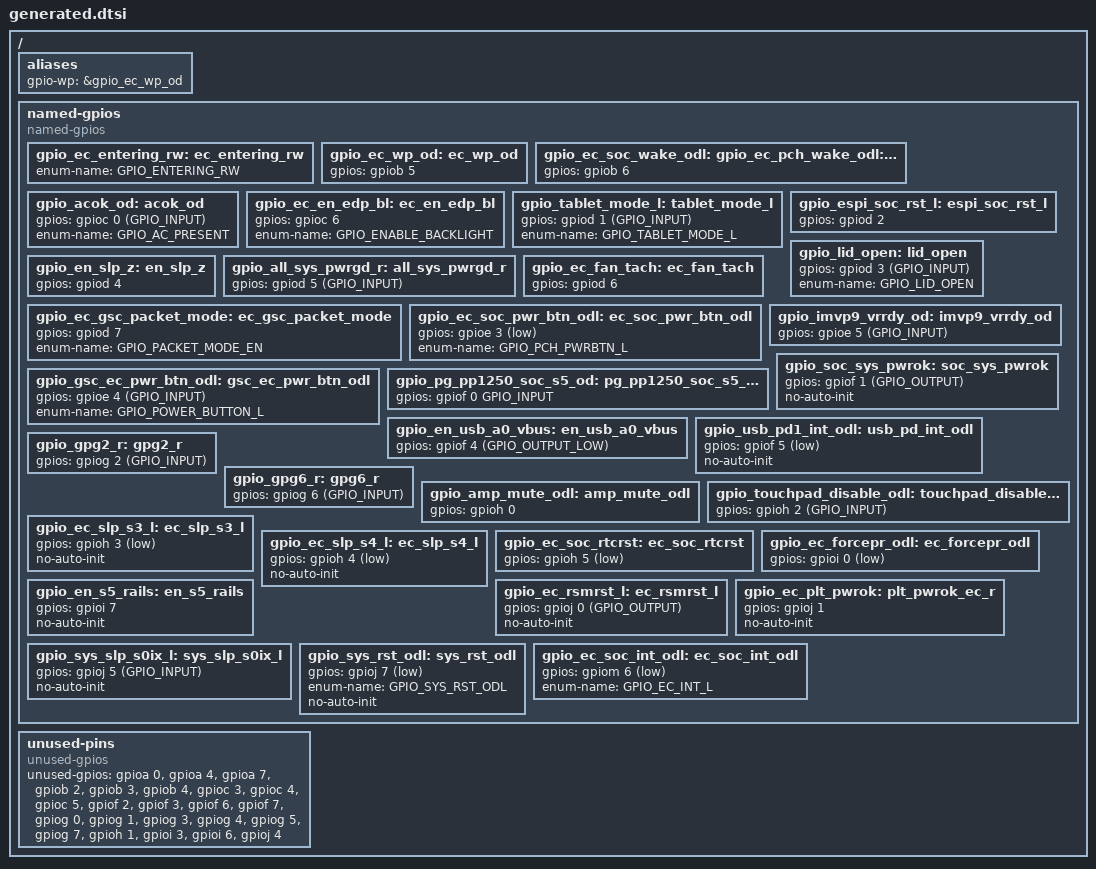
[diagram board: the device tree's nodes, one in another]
/* Copyright 2025 The ChromiumOS Authors
 * Use of this source code is governed by a BSD-style license that can be
 * found in the LICENSE file.
 */

/ {
	aliases {
		gpio-wp = &gpio_ec_wp_od;
	};

	named-gpios {
		compatible = "named-gpios";

		/* The legacy system code requires GPIO_ENTERING_RW symbol */
		gpio_ec_entering_rw: ec_entering_rw {
			enum-name = "GPIO_ENTERING_RW";
		};
            /*********** Port A *****************/
        /* GPA0: EC_KB_CAP_LED_L    */
        /* GPA1: PWM-EC_KB_BL_PWM   */
        /* GPA2: PWM-CHG_LED#_EC    */
        /* GPA3: PWM-AC_LED#_EC     */
        /* GPA4: FN_LED_L           */
		/* GPA5: PWM-PWR_LED_L      */
        /* GPA6: PWM-FAN_PWM_OD     */
        /* GPA7: ME_FLASH_EN_N      */

            /*********** Port B *****************/
        /* GPB0: UART_EC_RX_GSC_DBG_TX */
        /* GPB1: UART_EC_TX_GSC_DBG_RX */
        /* GPB2: NC                    */
		/* GPB3: tchscr_int_l		   */
        /* GPB4: CAMERA_WP_EC          */
		gpio_ec_wp_od: ec_wp_od {
			gpios = <&gpiob 5 (GPIO_INPUT | GPIO_ACTIVE_HIGH)>;
		};
		gpio_ec_soc_wake_odl: ec_soc_wake_odl {
			gpios = <&gpiob 6 (GPIO_OUTPUT | GPIO_OPEN_DRAIN | GPIO_ACTIVE_HIGH | GPIO_OUTPUT_INIT_HIGH)>;
		};

            /*********** Port C *****************/
		gpio_acok_od: acok_od {
			gpios = <&gpioc 0 (GPIO_INPUT)>;
			enum-name = "GPIO_AC_PRESENT";
		};
        /* GPC1: EC_I2C_PD_SCL          */
        /* GPC2: EC_I2C_PD_SDA          */
        /* GPC3: CPU_ID                 */
		/* GPC4: tchscr_report_en		*/
        /* GPC5: EC_PROJECT_ID          */
		gpio_ec_en_edp_bl: ec_en_edp_bl {
			gpios = <&gpioc 6 (GPIO_OUTPUT | GPIO_ACTIVE_HIGH | GPIO_OUTPUT_INIT_HIGH)>;
			enum-name = "GPIO_ENABLE_BACKLIGHT";
		};
        /* GPC7: EC_I2C_PROG_SCL        */

            /*********** Port D *****************/
        /* GPD0: EC_I2C_PROG_SDA        */
		gpio_tablet_mode_l: tablet_mode_l {
			gpios = <&gpiod 1 (GPIO_INPUT)>;
			enum-name = "GPIO_TABLET_MODE_L";
		};
		gpio_espi_soc_rst_l: espi_soc_rst_l {
			gpios = <&gpiod 2 (GPIO_INPUT | GPIO_VOLTAGE_1P8)>;
		};
		gpio_lid_open: lid_open {
			gpios = <&gpiod 3 (GPIO_INPUT)>;
			enum-name = "GPIO_LID_OPEN";
		};
		gpio_en_slp_z: en_slp_z {
			gpios = <&gpiod 4 (GPIO_OUTPUT | GPIO_ACTIVE_HIGH)>;
		};
		gpio_all_sys_pwrgd_r: all_sys_pwrgd_r {
			gpios = <&gpiod 5 (GPIO_INPUT)>;
		};
		gpio_ec_fan_tach: ec_fan_tach {
			gpios = <&gpiod 6 (GPIO_INPUT | GPIO_PULL_UP)>;
		};
		gpio_ec_gsc_packet_mode: ec_gsc_packet_mode {
			gpios = <&gpiod 7 (GPIO_OUTPUT | GPIO_ACTIVE_HIGH | GPIO_OUTPUT_INIT_LOW)>;
			enum-name = "GPIO_PACKET_MODE_EN";
		};

            /*********** Port E *****************/
        /* GPE0: EC_I2C_CHARGER_SCL     */
        /* GPE1: ISH_EC_I2C_SENSOR_SCL  */
        /* GPE2: ISH_EC_I2C_SENSOR_SDA  */
		gpio_ec_soc_pwr_btn_odl: ec_soc_pwr_btn_odl {
			gpios = <&gpioe 3 (GPIO_OUTPUT | GPIO_OPEN_DRAIN | GPIO_ACTIVE_LOW)>;
			enum-name = "GPIO_PCH_PWRBTN_L";
		};
		gpio_gsc_ec_pwr_btn_odl: gsc_ec_pwr_btn_odl {
			gpios = <&gpioe 4 (GPIO_INPUT)>;
			enum-name = "GPIO_POWER_BUTTON_L";
		};
		gpio_imvp9_vrrdy_od: imvp9_vrrdy_od {
			gpios = <&gpioe 5 (GPIO_INPUT)>;
		};
        /* GPE6: USB_C0_HV_DISABLE_EC   */
        /* GPE7: EC_I2C_CHARGER_SDA     */

            /*********** Port F *****************/
		gpio_pg_pp1250_soc_s5_od: pg_pp1250_soc_s5_od {
			gpios = <&gpiof 0 GPIO_INPUT>;
		};
		gpio_soc_sys_pwrok: soc_sys_pwrok {
			gpios = <&gpiof 1 (GPIO_OUTPUT)>;
			no-auto-init;
		};
        /* GPF2: PHASE_ID               */
		gpio_en_usb_a0_vbus: en_usb_a0_vbus {
			gpios = <&gpiof 4 (GPIO_OUTPUT_LOW)>;
		};
		gpio_usb_pd1_int_odl: usb_pd_int_odl {
			gpios = <&gpiof 5 (GPIO_INPUT | GPIO_ACTIVE_LOW)>;
			no-auto-init;
		};
        /* GPF6: EC_ACCEL_DB_INT_L      */
        /* GPF7: EC_ACCEL_MB_INT_L      */

            /*********** Port G *****************/
        /* GPG0: EC_SPARE_GPG0          */
        /* GPG1: EC_SPARE_STRAP_GPG2    */
		gpio_gpg2_r: gpg2_r {
			gpios = <&gpiog 2 (GPIO_INPUT)>;
		};
        /* GPG3: SPI_EC_CS_BIOS_L       */
        /* GPG4: SPI_EC_DO_BIOS_DI      */
        /* GPG5: SPI_EC_DI_BIOS_DO      */
		gpio_gpg6_r: gpg6_r {
			gpios = <&gpiog 6 (GPIO_INPUT)>;
		};
        /* GPG7: SPI_EC_CLK             */

            /*********** Port H *****************/
		gpio_amp_mute_odl: amp_mute_odl {
			gpios = <&gpioh 0 (GPIO_OUTPUT_HIGH | GPIO_OPEN_DRAIN)>;
		};
        /* GPH1: WOL_PWEN               */
		gpio_touchpad_disable_odl: touchpad_disable_odl{
			gpios = <&gpioh 2 (GPIO_INPUT)>;
		};
		gpio_ec_slp_s3_l: ec_slp_s3_l {
			gpios = <&gpioh 3 (GPIO_INPUT | GPIO_ACTIVE_LOW)>;
			no-auto-init;
		};
		gpio_ec_slp_s4_l: ec_slp_s4_l {
			gpios = <&gpioh 4 (GPIO_INPUT | GPIO_ACTIVE_LOW)>;
			no-auto-init;
		};
		gpio_ec_soc_rtcrst: ec_soc_rtcrst {
			gpios = <&gpioh 5 (GPIO_OUTPUT | GPIO_ACTIVE_LOW)>;
		};

            /*********** Port I *****************/
		gpio_ec_forcepr_odl: ec_forcepr_odl {
			gpios = <&gpioi 0 (GPIO_INPUT | GPIO_ACTIVE_LOW)>;
		};
        /* GPI1: ADC_ABMON              */
        /* GPI2: ADC_TEMP_SENSOR_3      */
        /* GPI3: ADC_I_ADP_EC           */
        /* GPI4: ADC_TEMP_SENSOR_1      */
        /* GPI5: ADC_TEMP_SENSOR_2      */
        /* GPI6: EC_TOP_SWAP            */
		/* Power sequencing signal needed by temp sensor driver */
		gpio_en_s5_rails: en_s5_rails {
			gpios = <&gpioi 7 (GPIO_OUTPUT | GPIO_ACTIVE_HIGH | GPIO_OUTPUT_INIT_LOW)>;
			no-auto-init;
		};

            /*********** Port J *****************/
		gpio_ec_rsmrst_l: ec_rsmrst_l {
			gpios = <&gpioj 0 (GPIO_OUTPUT)>;
			no-auto-init;
		};
		gpio_ec_plt_pwrok: plt_pwrok_ec_r {
			gpios = <&gpioj 1 (GPIO_OUTPUT | GPIO_ACTIVE_HIGH | GPIO_OUTPUT_INIT_LOW)>;
			no-auto-init;
		};
        /* GPJ4: EC_AC_PRESENT_OD_R     */
		gpio_sys_slp_s0ix_l: sys_slp_s0ix_l {
			gpios = <&gpioj 5 (GPIO_INPUT)>;
			no-auto-init;
		};
        /* GPJ6: TS_WOT                 */
		gpio_sys_rst_odl: sys_rst_odl {
			gpios = <&gpioj 7 (GPIO_OUTPUT | GPIO_OPEN_DRAIN | GPIO_ACTIVE_LOW | GPIO_OUTPUT_INIT_HIGH)>;
			enum-name = "GPIO_SYS_RST_ODL";
			no-auto-init;
		};

            /*********** Port M *****************/
		gpio_ec_soc_int_odl: ec_soc_int_odl {
			gpios = <&gpiom 6 (GPIO_OUTPUT | GPIO_OPEN_DRAIN | GPIO_ACTIVE_LOW)>;
			enum-name = "GPIO_EC_INT_L";
		};
	};

	unused-pins {
		compatible = "unused-gpios";

		unused-gpios =
			<&gpioa 0 0>, /* EC_KB_CAP_LED_L */
			<&gpioa 4 0>, /* FN_LED_L */
			<&gpioa 7 0>, /* ME_FLASH_EN_N */
			<&gpiob 2 0>, /* PCSPKR */
			<&gpiob 3 0>, /* tchscr_int_l */
			<&gpiob 4 0>, /* CAMERA_WP_EC */
			<&gpioc 3 0>, /* CPU_ID */
			<&gpioc 4 0>, /* TCHSCR_REPORT_EN */
			<&gpioc 5 0>, /* EC_PROJECT_ID */
			<&gpiof 2 0>, /* PHASE_ID */
			<&gpiof 3 0>, /* HDMI_GATE_EC */
			<&gpiof 6 0>, /* EC_ACCEL_DB_INT_L */
			<&gpiof 7 0>, /* EC_ACCEL_MB_INT_L */
			<&gpiog 0 0>, /* SPARE GPG0 */
			<&gpiog 1 0>, /* USB_C1_HV_DISABLE_EC */
			<&gpiog 3 0>, /* SPI_EC_CS_BIOS_L */
			<&gpiog 4 0>, /* SPI_EC_DO_BIOS_DI */
			<&gpiog 5 0>, /* SPI_EC_DI_BIOS_DO */
			<&gpiog 7 0>, /* SPI_EC_CLK */
			<&gpioh 1 0>, /* WOL_PWEN */
			<&gpioi 3 0>, /* I_ADP_EC */
			<&gpioi 6 0>, /* EC_TOP_SWAP */
			<&gpioj 4 0>; /* EC_AC_PRESENT_OD_R */
	};
};

/* The eSPI shim requires this GPIO nodelabel */
gpio_ec_pch_wake_odl: &gpio_ec_soc_wake_odl {};
